# SAM9X60 device description
Architecture: ARM926EJS; Family: SAM9; Series: SAM9X
Registers are 32-bit, read-write, no defined reset value unless marked. A register's access mark holds for its fields unless they carry their own. Offsets are from the block's base; [hi:lo] are bit positions; 'fields as' and 'values as' point back to an identical list.

## DBGU — Debug Unit
Instances: DBGU 0xFFFFF200
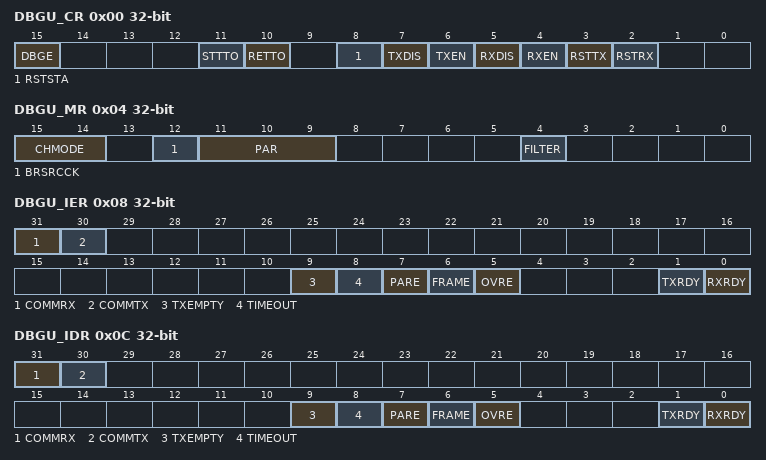
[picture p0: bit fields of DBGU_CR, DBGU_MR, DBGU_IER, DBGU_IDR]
0x00 DBGU_CR wo — Control Register
  [15] DBGE — Debug Enable
  [11] STTTO — Start Timeout
  [10] RETTO — Rearm Timeout
  [8] RSTSTA — Reset Status
  [7] TXDIS — Transmitter Disable
  [6] TXEN — Transmitter Enable
  [5] RXDIS — Receiver Disable
  [4] RXEN — Receiver Enable
  [3] RSTTX — Reset Transmitter
  [2] RSTRX — Reset Receiver
0x04 DBGU_MR — Mode Register
  [15:14] CHMODE — Channel Mode
    0=NORMAL (Normal mode); 1=AUTOMATIC (Automatic echo); 2=LOCAL_LOOPBACK; 3=REMOTE_LOOPBACK
  [12] BRSRCCK — Baud Rate Source Clock
    0=PERIPH_CLK (The baud rate is driven by the peripheral clock); 1=PMC_PCKGCLK (The baud rate is driven by a PMC-programmable clock PCKGCLK)
  [11:9] PAR — Parity Type
    0=EVEN (Even Parity); 1=ODD (Odd Parity); 2=SPACE (Space: parity forced to 0); 3=MARK (Mark: parity forced to 1); 4=NO (No parity)
  [4] FILTER — Receiver Digital Filter
    0=DISABLED (DBGU does not filter the receive line.); 1=ENABLED (DBGU filters the receive line using a three-sample filter (16x-bit clock) (2 over 3 majority).)
0x08 DBGU_IER wo — Interrupt Enable Register
  [31] COMMRX — Enable COMMRX (from ARM) Interrupt
  [30] COMMTX — Enable COMMTX (from ARM) Interrupt
  [9] TXEMPTY — Enable TXEMPTY Interrupt
  [8] TIMEOUT — Enable Timeout Interrupt
  [7] PARE — Enable Parity Error Interrupt
  [6] FRAME — Enable Framing Error Interrupt
  [5] OVRE — Enable Overrun Error Interrupt
  [1] TXRDY — Enable TXRDY Interrupt
  [0] RXRDY — Enable RXRDY Interrupt
0x0C DBGU_IDR wo — Interrupt Disable Register
  [31] COMMRX — Disable COMMRX (from ARM) Interrupt
  [30] COMMTX — Disable COMMTX (from ARM) Interrupt
  [9] TXEMPTY — Disable TXEMPTY Interrupt
  [8] TIMEOUT — Disable Timeout Interrupt
  [7] PARE — Disable Parity Error Interrupt
  [6] FRAME — Disable Framing Error Interrupt
  [5] OVRE — Disable Overrun Error Interrupt
  [1] TXRDY — Disable TXRDY Interrupt
  [0] RXRDY — Disable RXRDY Interrupt
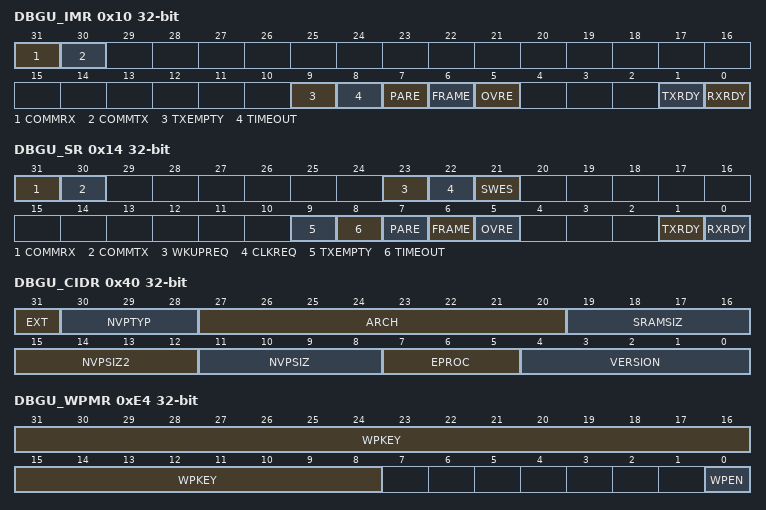
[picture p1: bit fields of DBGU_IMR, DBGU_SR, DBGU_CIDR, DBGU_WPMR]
0x10 DBGU_IMR ro — Interrupt Mask Register
  [31] COMMRX — Mask COMMRX (from ARM) Interrupt
  [30] COMMTX — Mask COMMTX (from ARM) Interrupt
  [9] TXEMPTY — Mask TXEMPTY Interrupt
  [8] TIMEOUT — Mask Timeout Interrupt
  [7] PARE — Mask Parity Error Interrupt
  [6] FRAME — Mask Framing Error Interrupt
  [5] OVRE — Mask Overrun Error Interrupt
  [1] TXRDY — Disable TXRDY Interrupt
  [0] RXRDY — Mask RXRDY Interrupt
0x14 DBGU_SR ro — Status Register
  [31] COMMRX — Debug Communication Channel Read Status
  [30] COMMTX — Debug Communication Channel Write Status
  [23] WKUPREQ — Wakeup Request
  [22] CLKREQ — Clock Request
  [21] SWES — SleepWalking Enable Status
  [9] TXEMPTY — Transmitter Empty
  [8] TIMEOUT — Receiver Timeout
  [7] PARE — Parity Error
  [6] FRAME — Framing Error
  [5] OVRE — Overrun Error
  [1] TXRDY — Transmitter Ready
  [0] RXRDY — Receiver Ready
0x18 DBGU_RHR ro — Receive Holding Register
  [7:0] RXCHR — Received Character
0x1C DBGU_THR wo — Transmit Holding Register
  [7:0] TXCHR — Character to be Transmitted
0x20 DBGU_BRGR — Baud Rate Generator Register
  [15:0] CD — Clock Divisor
0x28 DBGU_RTOR — Receiver Timeout Register
  [7:0] TO — Timeout Value
0x40 DBGU_CIDR ro — Chip ID Register
  [31] EXT — Extension Flag
  [30:28] NVPTYP — Nonvolatile Program Memory Type
    0=ROM; 1=ROMLESS (ROMless or on-chip Flash); 2=FLASH (Embedded Flash Memory); 3=ROM_FLASH (ROM and Embedded Flash MemoryNVPSIZ is ROM size NVPSIZ2 is Flash size); 4=SRAM (SRAM emulating ROM)
  [27:20] ARCH — Architecture Identifier
    25=AT91SAM9xx Series; 41=AT91SAM9XExx Series; 52=AT91x34 Series; 55=CAP7 (CAP7 Series); 57=CAP9 (CAP9 Series); 59=CAP11 (CAP11 Series); 64=AT91x40 Series; 66=AT91x42 Series; 85=AT91x55 Series; 96=AT91SAM7Axx Series; 97=AT91SAM7AQxx Series; 99=AT91x63 Series; 112=AT91SAM7Sxx Series; 113=AT91SAM7XCxx Series; 114=AT91SAM7SExx Series; 115=AT91SAM7Lxx Series; 117=AT91SAM7Xxx Series; 118=AT91SAM7SLxx Series; 128=ATSAM3UxC Series (100-pin version); 129=ATSAM3UxE Series (144-pin version); 131=ATSAM3AxC Series (100-pin version); 132=ATSAM3XxC Series (100-pin version); 133=ATSAM3XxE Series (144-pin version); 134=ATSAM3XxG Series (208/217-pin version); 136=ATSAM3SxA Series (48-pin version); 137=ATSAM3SxB Series (64-pin version); 138=ATSAM3SxC Series (100-pin version); 146=AT91x92 Series; 147=ATSAM3NxA Series (48-pin version); 148=ATSAM3NxB Series (64-pin version); 149=ATSAM3NxC Series (100-pin version); 152=ATSAM3SDxA Series (48-pin version); 153=ATSAM3SDxB Series (64-pin version); 154=ATSAM3SDxC Series (100-pin version); 165=ATSAMA5xx Series; 240=AT75Cxx Series
  [19:16] SRAMSIZ — Internal SRAM Size
    1=_1K (1 Kbytes); 2=_2K (2 Kbytes); 3=_6K (6 Kbytes); 4=_112K (112 Kbytes); 5=_4K (4 Kbytes); 6=_80K (80 Kbytes); 7=_160K (160 Kbytes); 8=_8K (8 Kbytes); 9=_16K (16 Kbytes); 10=_32K (32 Kbytes); 11=_64K (64 Kbytes); 12=_128K (128 Kbytes); 13=_256K (256 Kbytes); 14=_96K (96 Kbytes); 15=_512K (512 Kbytes)
  [15:12] NVPSIZ2 — Second Nonvolatile Program Memory Size
    0=NONE; 1=_8K (8 Kbytes); 2=_16K (16 Kbytes); 3=_32K (32 Kbytes); 5=_64K (64 Kbytes); 7=_128K (128 Kbytes); 9=_256K (256 Kbytes); 10=_512K (512 Kbytes); 12=_1024K (1024 Kbytes); 14=_2048K (2048 Kbytes)
  [11:8] NVPSIZ — Nonvolatile Program Memory Size
    values as NVPSIZ2
  [7:5] EPROC — Embedded Processor
    1=ARM946ES; 2=ARM7TDMI; 3=CM3 (Cortex-M3); 4=ARM920T; 5=ARM926EJS; 6=CA5 (Cortex-A5)
  [4:0] VERSION — Version of the Device
0x44 DBGU_EXID ro — Chip ID Extension Register
  [31:0] EXID — Chip ID Extension
0x48 DBGU_FNR — Force NTRST Register
  [0] FNTRST — Force NTRST
0xE4 DBGU_WPMR — Write Protection Mode Register
  [31:8] WPKEY — Write Protection Key
    0x554152=PASSWD (Writing any other value in this field aborts the write operation.Always reads as 0.)
  [0] WPEN — Write Protection Enable
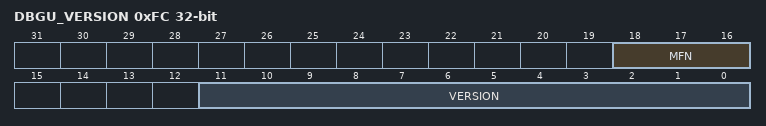
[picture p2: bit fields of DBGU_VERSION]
0xFC DBGU_VERSION ro — Version Register
  [18:16] MFN — Metal Fix Number
  [11:0] VERSION — Hardware Module Version
